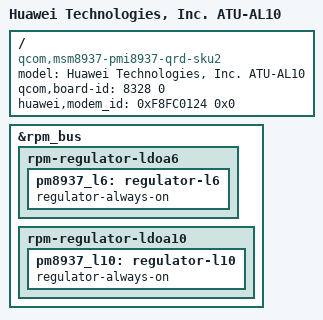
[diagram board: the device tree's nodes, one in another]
/*
 * Copyright (c) 2016, The Linux Foundation. All rights reserved.
 *
 * This program is free software; you can redistribute it and/or modify
 * it under the terms of the GNU General Public License version 2 and
 * only version 2 as published by the Free Software Foundation.
 *
 * This program is distributed in the hope that it will be useful,
 * but WITHOUT ANY WARRANTY; without even the implied warranty of
 * MERCHANTABILITY or FITNESS FOR A PARTICULAR PURPOSE.  See the
 * GNU General Public License for more details.
 */

/dts-v1/;
#include "huawei_msm8937_nopmi_base.dtsi"
#include "lcdkit/aum_al10_va/devkit_lcd.dtsi"
#include "lcdkit/default/devkit_lcd.dtsi"
#include "huawei_msm8937_atu_al10_va/huawei.dtsi"
/ {
	model = "Huawei Technologies, Inc. ATU-AL10";
	compatible = "qcom,msm8937-pmi8937-qrd-sku2",
                 "qcom,msm8937-qrd", "qcom,msm8937", "qcom,qrd";
	qcom,board-id= <8328 0>;
	huawei,modem_id = <0xF8FC0124 0x0>;
};
&rpm_bus {
	rpm-regulator-ldoa6 {
		pm8937_l6: regulator-l6 {
			regulator-always-on;
		};
	};
	rpm-regulator-ldoa10 {
		pm8937_l10: regulator-l10 {
			regulator-always-on;
		};
	};
};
